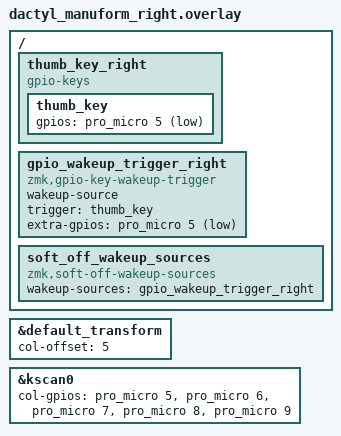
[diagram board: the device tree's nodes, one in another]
#include "dactyl_manuform.dtsi"

&default_transform { // The matrix transform for this board is 6 columns over because the left half is 5 columns wide according to the matrix.
    col-offset = <5>;
};

&kscan0 {
    col-gpios
        = <&pro_micro 5 GPIO_ACTIVE_HIGH>
        , <&pro_micro 6 GPIO_ACTIVE_HIGH>
        , <&pro_micro 7 GPIO_ACTIVE_HIGH>
        , <&pro_micro 8 GPIO_ACTIVE_HIGH>
        , <&pro_micro 9 GPIO_ACTIVE_HIGH>
        ;
};

/ {
    thumb_key_right: thumb_key_right {
        compatible = "gpio-keys";
        thumb_key: thumb_key {
            gpios = <&pro_micro 5 (GPIO_ACTIVE_LOW | GPIO_PULL_UP)>;
        };
    };

    gpio_wakeup_trigger_right: gpio_wakeup_trigger_right {
        compatible = "zmk,gpio-key-wakeup-trigger";
        wakeup-source;
        trigger = <&thumb_key>;
        extra-gpios = <&pro_micro 5 (GPIO_ACTIVE_LOW | GPIO_PULL_UP)>;
    };

    soft_off_wakeup_sources {
        compatible = "zmk,soft-off-wakeup-sources";
        wakeup-sources = <&gpio_wakeup_trigger_right>;
    };
};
